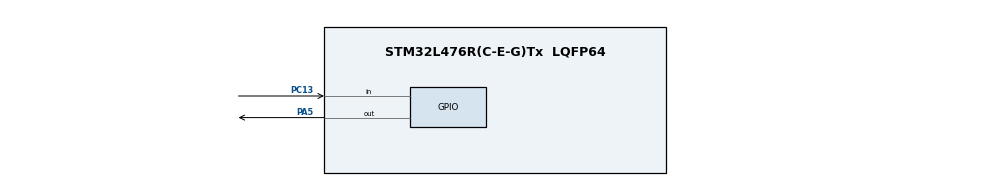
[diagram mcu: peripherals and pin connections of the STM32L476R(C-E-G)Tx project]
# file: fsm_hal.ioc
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FREERTOS.Tasks01=defaultTask,0,128,StartDefaultTask,Default,NULL,Dynamic,NULL,NULL;Led,-3,128,StartLed,Default,NULL,Dynamic,NULL,NULL;Boton,-3,128,StartBoton,Default,NULL,Dynamic,NULL,NULL;myTask04,-3,128,StartTask04,Default,NULL,Dynamic,NULL,NULL
Mcu.Family=STM32L4
Mcu.Name=STM32L476R(C-E-G)Tx
Mcu.Package=LQFP64
NVIC.PriorityGroup=NVIC_PRIORITYGROUP_4
PA5.Signal=GPIO_Output
PC13.Signal=GPIO_Input
ProjectManager.HeapSize=0x200
ProjectManager.StackSize=0x400
ProjectManager.TargetToolchain=STM32CubeIDE
RCC.HSE_VALUE=8000000
RCC.HSI_VALUE=16000000
RCC.LSE_VALUE=32768
RCC.MSI_VALUE=4000000
RCC.VCOOutputFreq_Value=32000000
VP_FREERTOS_VS_CMSIS_V1.Mode=CMSIS_V1
board=custom

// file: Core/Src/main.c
/* USER CODE BEGIN Header */
/**
  ******************************************************************************
  * @file           : main.c
  * @brief          : Main program body
  ******************************************************************************
  * @attention
  *
  * <h2><center>&copy; Copyright (c) 2020 STMicroelectronics.
  * All rights reserved.</center></h2>
  *
  * This software component is licensed by ST under BSD 3-Clause license,
  * the "License"; You may not use this file except in compliance with the
  * License. You may obtain a copy of the License at:
  *                        opensource.org/licenses/BSD-3-Clause
  *
  ******************************************************************************
  */
/* USER CODE END Header */

#include "main.h"
#include "cmsis_os.h"

/* USER CODE BEGIN Includes */
//#include "fsm.h"

/* USER CODE END Includes */

osThreadId defaultTaskHandle;
osThreadId LedHandle;
osThreadId BotonHandle;
/* USER CODE BEGIN PV */
uint32_t marca=0;

/* USER CODE END PV */

void SystemClock_Config(void);
static void MX_GPIO_Init(void);
void StartDefaultTask(void const * argument);
void StartLed(void const * argument);
void StartBoton(void const * argument);

int main(void)
{

  /* MCU Configuration--------------------------------------------------------*/

  /* Reset of all peripherals, Initializes the Flash interface and the Systick. */
  HAL_Init();

  /* Configure the system clock */
  SystemClock_Config();

  /* Initialize all configured peripherals */
  MX_GPIO_Init();
  marca=HAL_GetTick();

  /* Create the thread(s) */
  /* definition and creation of defaultTask */
  osThreadDef(defaultTask, StartDefaultTask, osPriorityNormal, 0, 128);
  defaultTaskHandle = osThreadCreate(osThread(defaultTask), NULL);

  /* definition and creation of Led */
  osThreadDef(Led, StartLed, osPriorityIdle, 0, 128);
  LedHandle = osThreadCreate(osThread(Led), NULL);

  /* definition and creation of Boton */
  osThreadDef(Boton, StartBoton, osPriorityIdle, 0, 128);
  BotonHandle = osThreadCreate(osThread(Boton), NULL);

  /* USER CODE BEGIN RTOS_THREADS */
  /* add threads, ... */

  /* Set thread 2 in suspend state */
  //osThreadSuspend(LedHandle);
  /* USER CODE END RTOS_THREADS */

  /* Start scheduler */
  osKernelStart();

  /* We should never get here as control is now taken by the scheduler */
  /* Infinite loop */
  while (1)
  {

    /* USER CODE BEGIN 3 */

	if (HAL_GetTick()>marca){//Si ha pasado un milisegundo desde la ultima ejecucion
	  BotonHandler();
	  LedHandler();
	  marca=HAL_GetTick();  //Almacene el tiempo actual
	}
  }
  /* USER CODE END 3 */
}

void SystemClock_Config(void)
{
  RCC_OscInitTypeDef RCC_OscInitStruct = {0};
  RCC_ClkInitTypeDef RCC_ClkInitStruct = {0};

  /** Initializes the CPU, AHB and APB busses clocks
  */
  RCC_OscInitStruct.OscillatorType = RCC_OSCILLATORTYPE_MSI;
  RCC_OscInitStruct.MSIState = RCC_MSI_ON;
  RCC_OscInitStruct.MSICalibrationValue = 0;
  RCC_OscInitStruct.MSIClockRange = RCC_MSIRANGE_6;
  RCC_OscInitStruct.PLL.PLLState = RCC_PLL_NONE;
  if (HAL_RCC_OscConfig(&RCC_OscInitStruct) != HAL_OK)
  {
    Error_Handler();
  }
  /** Initializes the CPU, AHB and APB busses clocks
  */
  RCC_ClkInitStruct.ClockType = RCC_CLOCKTYPE_HCLK|RCC_CLOCKTYPE_SYSCLK
                              |RCC_CLOCKTYPE_PCLK1|RCC_CLOCKTYPE_PCLK2;
  RCC_ClkInitStruct.SYSCLKSource = RCC_SYSCLKSOURCE_MSI;
  RCC_ClkInitStruct.AHBCLKDivider = RCC_SYSCLK_DIV1;
  RCC_ClkInitStruct.APB1CLKDivider = RCC_HCLK_DIV1;
  RCC_ClkInitStruct.APB2CLKDivider = RCC_HCLK_DIV1;

  if (HAL_RCC_ClockConfig(&RCC_ClkInitStruct, FLASH_LATENCY_0) != HAL_OK)
  {
    Error_Handler();
  }
  /** Configure the main internal regulator output voltage
  */
  if (HAL_PWREx_ControlVoltageScaling(PWR_REGULATOR_VOLTAGE_SCALE1) != HAL_OK)
  {
    Error_Handler();
  }
}

static void MX_GPIO_Init(void)
{
  GPIO_InitTypeDef GPIO_InitStruct = {0};

  /* GPIO Ports Clock Enable */
  __HAL_RCC_GPIOC_CLK_ENABLE();
  __HAL_RCC_GPIOA_CLK_ENABLE();

  /*Configure GPIO pin Output Level */
  HAL_GPIO_WritePin(GPIOA, GPIO_PIN_5, GPIO_PIN_RESET);

  /*Configure GPIO pin : PC13 */
  GPIO_InitStruct.Pin = GPIO_PIN_13;
  GPIO_InitStruct.Mode = GPIO_MODE_INPUT;
  GPIO_InitStruct.Pull = GPIO_NOPULL;
  HAL_GPIO_Init(GPIOC, &GPIO_InitStruct);

  /*Configure GPIO pin : PA5 */
  GPIO_InitStruct.Pin = GPIO_PIN_5;
  GPIO_InitStruct.Mode = GPIO_MODE_OUTPUT_PP;
  GPIO_InitStruct.Pull = GPIO_NOPULL;
  GPIO_InitStruct.Speed = GPIO_SPEED_FREQ_LOW;
  HAL_GPIO_Init(GPIOA, &GPIO_InitStruct);

}

void StartDefaultTask(void const * argument)
{
  for(;;)
  {
    osDelay(1);
  }
}

void StartLed(void const * argument)
{
  /* USER CODE BEGIN StartLed */
	  uint32_t count = 0;
	  (void) argument;
  /* Infinite loop */
  for(;;)
  {
	    //count = osKernelSysTick() + 10;

	    //while (count > osKernelSysTick())
	    //{
	    	 LedHandler();
	    //}

	    /* Resume Thread 2 */
	    //osThreadResume(BotonHandle);
	    /* Suspend Thread 1 : current thread */
	    //osThreadSuspend(LedHandle);
  }
  /* USER CODE END StartLed */
}

void StartBoton(void const * argument)
{
  /* USER CODE BEGIN StartBoton */
  /* Infinite loop */
	  uint32_t count = 0;
	  (void) argument;
/* Infinite loop */
for(;;)
{
	    //count = osKernelSysTick() + 10;

	    //while (count > osKernelSysTick())
	    //{
	    	BotonHandler();
	    //}

	    /* Resume Thread 2 */
	    //osThreadResume(LedHandle);
	    /* Suspend Thread 1 : current thread */
	    //osThreadSuspend(BotonHandle);
}
  /* USER CODE END StartBoton */
}

void Error_Handler(void)
{
}

/************************ (C) COPYRIGHT STMicroelectronics *****END OF FILE****/
